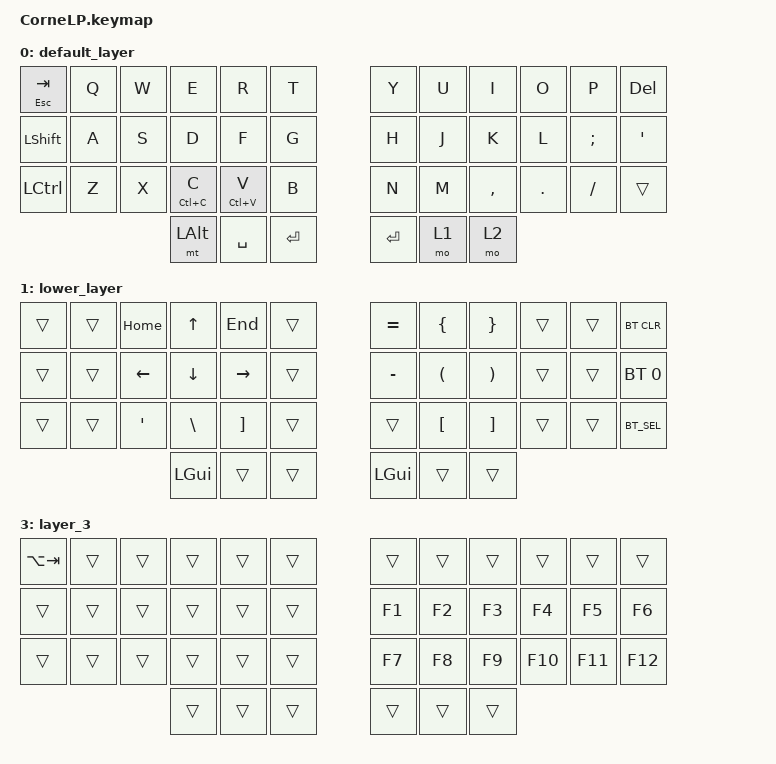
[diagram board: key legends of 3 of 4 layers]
/*
 * Copyright (c) 2020 The ZMK Contributors
 *
 * SPDX-License-Identifier: MIT
 */

#include <behaviors.dtsi>
#include <dt-bindings/zmk/keys.h>
#include <dt-bindings/zmk/bt.h>

#define DEFAULT 0
#define LOWER 1
#define RAISE 2
#define L3 3

/ {
    keymap {
                compatible = "zmk,keymap";

                default_layer {
// -----------------------------------------------------------------------------------------
// | TAB  |  Q  |  W  |  E  |  R  |  T  |         |  Y  |  U   |  I  |  O  |  P  |  DEL |
// | SHFT |  A  |  S  |  D  |  F  |  G  |         |  H  |  J   |  K  |  L  |  ;  |  '   |
// | CTRL |  Z  |  X  |  C  |  V  |  B  |         |  N  |  M   |  ,  |  .  |  /  |      |
//                    | ALT |SPACE|ENTER|         |BKCSP|  L1  | L2  |

                        bindings = <
   &mt ESC TAB &kp Q &kp W &kp E        &kp R        &kp T        &kp Y &kp U  &kp I     &kp O   &kp P    &kp DEL
   &kp LSHFT   &kp A &kp S &kp D        &kp F        &kp G        &kp H &kp J  &kp K     &kp L   &kp SEMI &kp SQT
   &kp LCTRL   &kp Z &kp X &mt LC(C) C  &mt LC(V) V  &kp B        &kp N &kp M  &kp COMMA &kp DOT &kp FSLH &trans
                &mt LALT   &kp SPACE  &kp ENTER                   &kp RET &mo 1 &mo 2
                        >;
                };
                
                lower_layer {
// ----------------------------------------------------------------------------------
// |    |    | HOME| UP  | END |     |         |     |  {  |  }  |     |      | BT_CLR  | 
// |    |    | LFT | DWN | RGT |     |         |  =  |  (  |  )  |     |      |  BT_1   |
// |    |    |  '  |  \  |  ]  |     |         |  -  |  [  |  ]  |     |      |  BT_2   |
//                 | LGUI|     |     |         |     |     |     |

                        bindings = <
   &trans   &trans  &kp HOME  &kp UP   &kp END   &trans          &kp EQUAL &kp LBRC   &kp RBRC &trans  &trans  &bt BT_CLR
   &trans   &trans  &kp LEFT  &kp DOWN  &kp RIGHT &trans         &kp MINUS  &kp LPAR &kp RPAR  &trans  &trans  &bt BT_SEL 0
   &trans &trans    &kp SQT   &kp BSLH  &kp RBKT   &trans        &trans     &kp LBKT  &kp RBKT  &trans &trans  &kp BT_SEL 1
                              &kp LGUI    &trans    &trans         &kp LGUI    &trans      &trans
                        >;
                };

                raise_layer {
// -----------------------------------------------------------------------------------------
// |     |  1   |  2   |  3   |  4  | 5  |         |  6  |  7   |  8  |  9  | 0   |    |
// |     |  !   |  @   |  #   |  $  | %  |         | F1  | F2  | F3  | F4  |  F5 | F6  |
// |     |      |  \   |  &   |  *  | ^  |         | F7  | F8  | F9  | F10 | F11 | F12 |
//                     |      |SPACE|BKSP|         |     |     |      |

                        bindings = <
   &trans   &kp N1    &kp N2       &kp N3 g   &kp N4     &kp N5         &kp N6    &kp N7  &kp N8    &kp N9    &kp N0  &trans
   &trans   &kp EXCL  &kp AT      &kp HASH   &kp DLLR   &kp PRCNT     &kp F1    &kp F2  &kp F3  &kp F4   &kp F5    &kp F6
   &trans   &trans   &kp BSLH    &kp AMPS   &kp STAR   &kp CARET      &kp F7    &kp F8  &kp F9  &kp F10  &kp F11   &kp F12
                    	  &kp LGUI    &trans    &kp SPACE   &kp RET       &trans   &trans    &trans
                        >;
                };
                
                layer_3 {
// ----------------------------------------------------------------------------------
// |ALTTAB|    |     |     |     |     |         |     |     |     |     |     |     | 
// |      |    |     |     |     |     |         | F1  | F2  | F3  | F4  |  F5 | F6  |
// |      |    |     |     |     |     |         | F7  | F8  | F9  | F10 | F11 | F12 |
//                   |     |     |     |         |     |     |     |

                        bindings = <
   &kp LA(TAB)  &trans  &trans  &trans   &trans  &trans          &trans    &trans  &trans  &trans   &trans  &trans
   &trans       &trans  &trans  &trans   &trans  &trans          &kp F1    &kp F2  &kp F3  &kp F4   &kp F5  &kp F6
   &trans       &trans  &trans  &trans   &trans  &trans          &kp F7    &kp F8  &kp F9  &kp F10  &kp F11  &kp F12
                            &trans    &trans  &trans          &trans   &trans  &trans
                        >;
                };
        };
};
